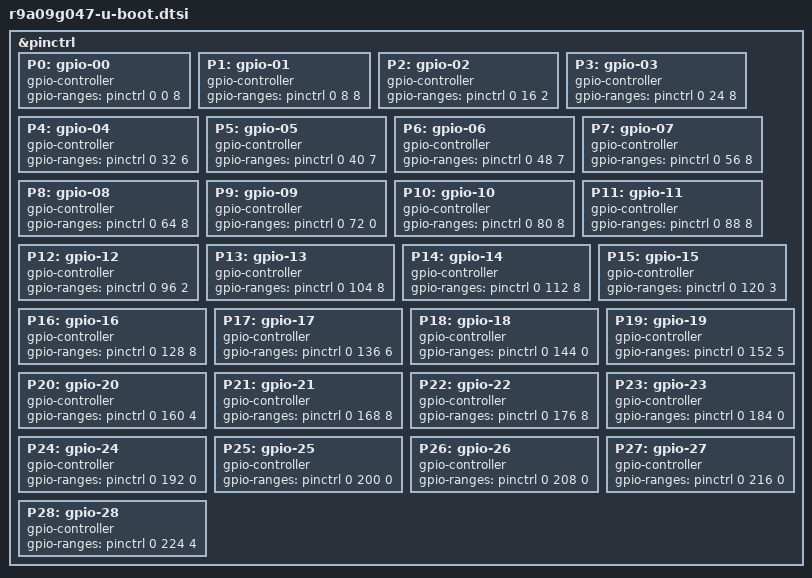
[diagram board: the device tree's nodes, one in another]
// SPDX-License-Identifier: GPL-2.0
/*
 * RZ/G3E (R9A09G047) SoC, specific setting for u-boot
 *
 * Copyright (C) 2023 Renesas Electronics Corp.
 */

&pinctrl {
	P0: gpio-00 {
		gpio-controller;
		#gpio-cells = <2>;
		gpio-ranges = <&pinctrl 0 0 8>;
	};

	P1: gpio-01 {
		gpio-controller;
		#gpio-cells = <2>;
		gpio-ranges = <&pinctrl 0 8 8>;
	};

	P2: gpio-02 {
		gpio-controller;
		#gpio-cells = <2>;
		gpio-ranges = <&pinctrl 0 16 2>;
	};

	P3: gpio-03 {
		gpio-controller;
		#gpio-cells = <2>;
		gpio-ranges = <&pinctrl 0 24 8>;
	};

	P4: gpio-04 {
		gpio-controller;
		#gpio-cells = <2>;
		gpio-ranges = <&pinctrl 0 32 6>;
	};

	P5: gpio-05 {
		gpio-controller;
		#gpio-cells = <2>;
		gpio-ranges = <&pinctrl 0 40 7>;
	};

	P6: gpio-06 {
		gpio-controller;
		#gpio-cells = <2>;
		gpio-ranges = <&pinctrl 0 48 7>;
	};

	P7: gpio-07 {
		gpio-controller;
		#gpio-cells = <2>;
		gpio-ranges = <&pinctrl 0 56 8>;
	};

	P8: gpio-08 {
		gpio-controller;
		#gpio-cells = <2>;
		gpio-ranges = <&pinctrl 0 64 8>;
	};

	P9: gpio-09 {
		gpio-controller;
		#gpio-cells = <2>;
		gpio-ranges = <&pinctrl 0 72 0>;
	};

	P10: gpio-10 {
		gpio-controller;
		#gpio-cells = <2>;
		gpio-ranges = <&pinctrl 0 80 8>;
	};

	P11: gpio-11 {
		gpio-controller;
		#gpio-cells = <2>;
		gpio-ranges = <&pinctrl 0 88 8>;
	};

	P12: gpio-12 {
		gpio-controller;
		#gpio-cells = <2>;
		gpio-ranges = <&pinctrl 0 96 2>;
	};

	P13: gpio-13 {
		gpio-controller;
		#gpio-cells = <2>;
		gpio-ranges = <&pinctrl 0 104 8>;
	};

	P14: gpio-14 {
		gpio-controller;
		#gpio-cells = <2>;
		gpio-ranges = <&pinctrl 0 112 8>;
	};

	P15: gpio-15 {
		gpio-controller;
		#gpio-cells = <2>;
		gpio-ranges = <&pinctrl 0 120 3>;
	};

	P16: gpio-16 {
		gpio-controller;
		#gpio-cells = <2>;
		gpio-ranges = <&pinctrl 0 128 8>;
	};

	P17: gpio-17 {
		gpio-controller;
		#gpio-cells = <2>;
		gpio-ranges = <&pinctrl 0 136 6>;
	};

	P18: gpio-18 {
		gpio-controller;
		#gpio-cells = <2>;
		gpio-ranges = <&pinctrl 0 144 0>;
	};

	P19: gpio-19 {
		gpio-controller;
		#gpio-cells = <2>;
		gpio-ranges = <&pinctrl 0 152 5>;
	};

	P20: gpio-20 {
		gpio-controller;
		#gpio-cells = <2>;
		gpio-ranges = <&pinctrl 0 160 4>;
	};

	P21: gpio-21 {
		gpio-controller;
		#gpio-cells = <2>;
		gpio-ranges = <&pinctrl 0 168 8>;
	};

	P22: gpio-22 {
		gpio-controller;
		#gpio-cells = <2>;
		gpio-ranges = <&pinctrl 0 176 8>;
	};

	P23: gpio-23 {
		gpio-controller;
		#gpio-cells = <2>;
		gpio-ranges = <&pinctrl 0 184 0>;
	};

	P24: gpio-24 {
		gpio-controller;
		#gpio-cells = <2>;
		gpio-ranges = <&pinctrl 0 192 0>;
	};

	P25: gpio-25 {
		gpio-controller;
		#gpio-cells = <2>;
		gpio-ranges = <&pinctrl 0 200 0>;
	};

	P26: gpio-26 {
		gpio-controller;
		#gpio-cells = <2>;
		gpio-ranges = <&pinctrl 0 208 0>;
	};

	P27: gpio-27 {
		gpio-controller;
		#gpio-cells = <2>;
		gpio-ranges = <&pinctrl 0 216 0>;
	};

	P28: gpio-28 {
		gpio-controller;
		#gpio-cells = <2>;
		gpio-ranges = <&pinctrl 0 224 4>;
	};
};
